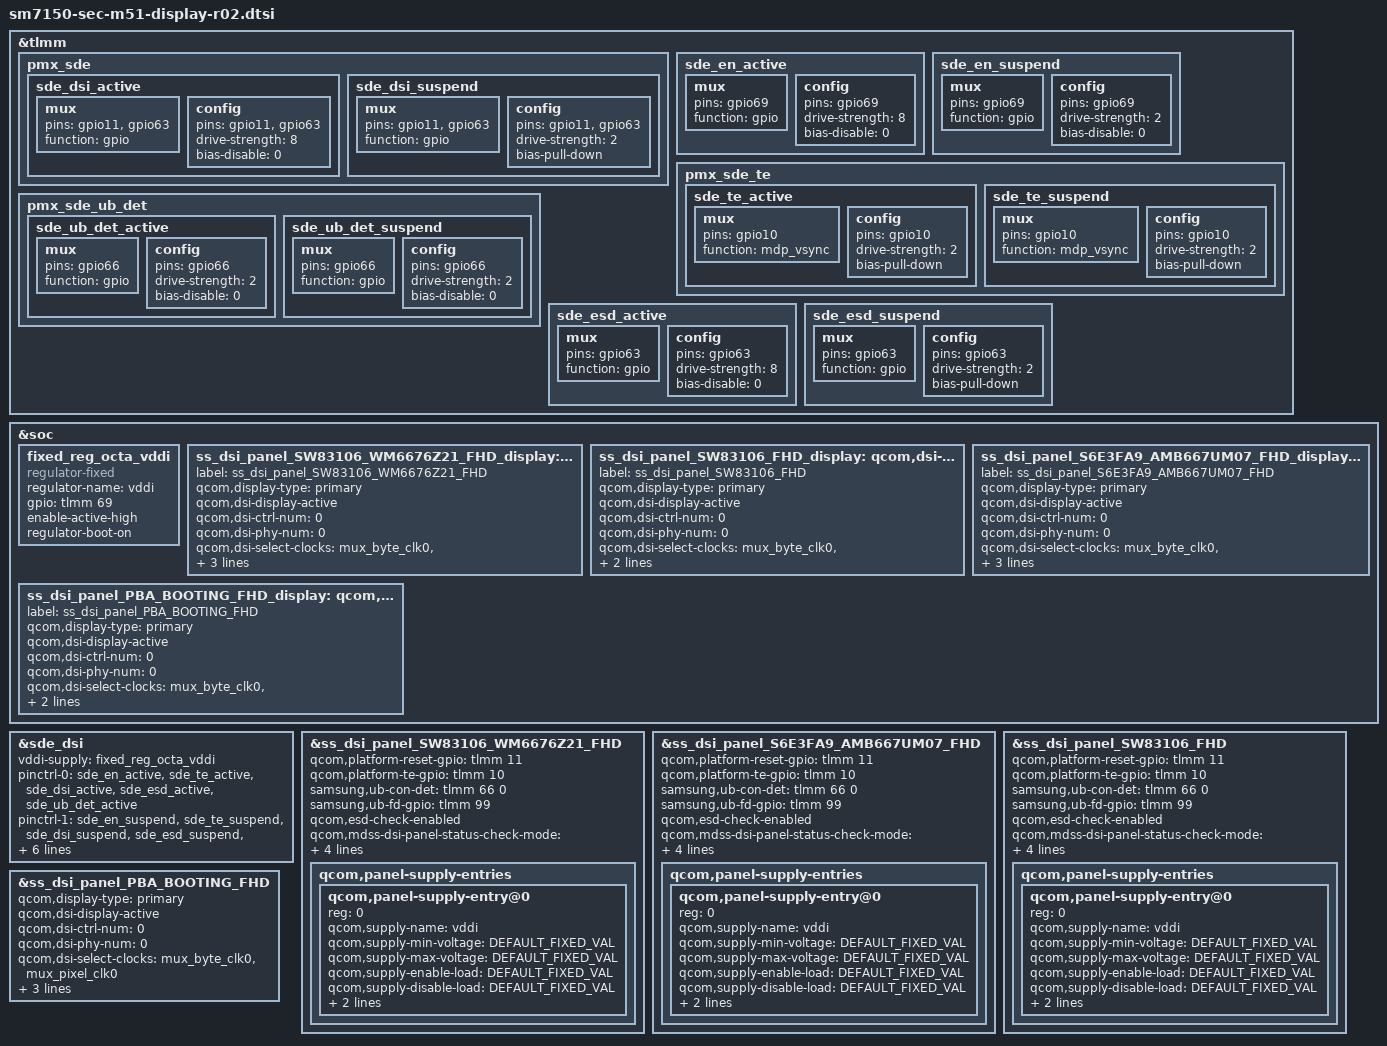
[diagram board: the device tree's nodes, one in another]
/* Copyright (c) 2016-2019, The Linux Foundation. All rights reserved.
 *
 * This program is free software; you can redistribute it and/or modify
 * it under the terms of the GNU General Public License version 2 and
 * only version 2 as published by the Free Software Foundation.
 *
 * This program is distributed in the hope that it will be useful,
 * but WITHOUT ANY WARRANTY; without even the implied warranty of
 * MERCHANTABILITY or FITNESS FOR A PARTICULAR PURPOSE.  See the
 * GNU General Public License for more details.
 */
#include "../../../../../../drivers/gpu/drm/msm/samsung/SW83106/dsi_panel_SW83106_fhd_octa_cmd.dtsi"
#include "../../../../../../drivers/gpu/drm/msm/samsung/SW83106_WM6676Z21/dsi_panel_SW83106_WM6676Z21_fhd_octa_cmd.dtsi"
#include "../../../../../../drivers/gpu/drm/msm/samsung/S6E3FA9_AMB667UM07/dsi_panel_S6E3FA9_AMB667UM07_fhd_octa_cmd.dtsi"
#include "../../../../../../drivers/gpu/drm/msm/samsung/SELF_DISPLAY/self_display_cmd_FA9.dtsi"
#include "../../../../../../drivers/gpu/drm/msm/samsung/PBA_BOOTING/dsi_panel_PBA_BOOTING_fhd_video.dtsi"

#define DEFAULT_FIXED_VAL	0

&tlmm {
	pmx_sde: pmx_sde {
		sde_dsi_active: sde_dsi_active {
			mux {
				pins = "gpio11", "gpio63";
				function = "gpio";
			};

			config {
				pins = "gpio11", "gpio63";
				drive-strength = <8>;   /* 8 mA */
				bias-disable = <0>;   /* no pull */
			};
		};
		sde_dsi_suspend: sde_dsi_suspend {
			mux {
				pins = "gpio11", "gpio63";
				function = "gpio";
			};

			config {
				pins = "gpio11", "gpio63";
				drive-strength = <2>;   /* 2 mA */
				bias-pull-down;         /* PULL DOWN */
			};
		};
	};

		sde_en_active: sde_en_active {
			mux {
				pins = "gpio69";
				function = "gpio";
			};

			config {
				pins = "gpio69";
				drive-strength = <8>;   /* 8 mA */
				bias-disable = <0>;   /* no pull */
			};
		};
		sde_en_suspend: sde_en_suspend {
			mux {
				pins = "gpio69";
				function = "gpio";
			};

			config {
				pins = "gpio69";
				drive-strength = <2>;   /* 2 mA */
				bias-disable = <0>;   /* no pull */
			};
		};

	pmx_sde_te {
		sde_te_active: sde_te_active {
			mux {
				pins = "gpio10";
				function = "mdp_vsync";
			};

			config {
				pins = "gpio10";
				drive-strength = <2>;   /* 2 mA */
				bias-pull-down;         /* PULL DOWN */
			};
		};

		sde_te_suspend: sde_te_suspend {
			mux {
				pins = "gpio10";
				function = "mdp_vsync";
			};

			config {
				pins = "gpio10";
				drive-strength = <2>;   /* 2 mA */
				bias-pull-down;         /* PULL DOWN */
			};
		};
	};

	pmx_sde_ub_det {
		sde_ub_det_active: sde_ub_det_active {	/* UB_CON_DET */
			mux {
				pins = "gpio66";
				function = "gpio";
			};

			config {
				pins = "gpio66";
				drive-strength = <2>;   /* 2 mA */
				bias-disable = <0>;   /* no pull */
			};
		};

		sde_ub_det_suspend: sde_ub_det_suspend {
			mux {
				pins = "gpio66";
				function = "gpio";
			};

			config {
				pins = "gpio66";
				drive-strength = <2>;   /* 2 mA */
				bias-disable = <0>;   /* no pull */
			};
		};
	};

	sde_esd_active: sde_esd_active {  /*EL_ON1_DET gpio*/
		mux {
			pins = "gpio63";
			function = "gpio";
		};

		config {
			pins = "gpio63";
			drive-strength = <8>;   /* 8 mA */
			bias-disable = <0>;   /* no pull */
		};
	};
	sde_esd_suspend: sde_esd_suspend {
		mux {
			pins = "gpio63";
			function = "gpio";
		};

		config {
			pins = "gpio63";
			drive-strength = <2>;   /* 2 mA */
			bias-pull-down;         /* PULL DOWN */
		};
	};
};

&soc {
	fixed_reg_octa_vddi: fixed_reg_octa_vddi {
		compatible = "regulator-fixed";
		status = "okay";
		regulator-name = "vddi";
		gpio = <&tlmm 69 0>; /* LCD_EN : 3.0 & 1.8 V */
		enable-active-high;
		regulator-boot-on;
	};
};

&soc {
	ss_dsi_panel_SW83106_WM6676Z21_FHD_display: qcom,dsi-display@0 {
		label = "ss_dsi_panel_SW83106_WM6676Z21_FHD";
		qcom,display-type = "primary";
		qcom,dsi-display-active;

		qcom,dsi-ctrl-num = <0>;
		qcom,dsi-phy-num = <0>;
		qcom,dsi-select-clocks = "mux_byte_clk0", "mux_pixel_clk0";

		qcom,dsi-panel = <&ss_dsi_panel_SW83106_WM6676Z21_FHD>;
	};

	ss_dsi_panel_SW83106_FHD_display: qcom,dsi-display@1 {
		label = "ss_dsi_panel_SW83106_FHD";
		qcom,display-type = "primary";
		qcom,dsi-display-active;

		qcom,dsi-ctrl-num = <0>;
		qcom,dsi-phy-num = <0>;
		qcom,dsi-select-clocks = "mux_byte_clk0", "mux_pixel_clk0";

		qcom,dsi-panel = <&ss_dsi_panel_SW83106_FHD>;
	};

	ss_dsi_panel_S6E3FA9_AMB667UM07_FHD_display: qcom,dsi-display@2 {
		label = "ss_dsi_panel_S6E3FA9_AMB667UM07_FHD";
		qcom,display-type = "primary";
		qcom,dsi-display-active;

		qcom,dsi-ctrl-num = <0>;
		qcom,dsi-phy-num = <0>;
		qcom,dsi-select-clocks = "mux_byte_clk0", "mux_pixel_clk0";

		qcom,dsi-panel = <&ss_dsi_panel_S6E3FA9_AMB667UM07_FHD>;
	};

	/* PBA */
	ss_dsi_panel_PBA_BOOTING_FHD_display: qcom,dsi-display@3 {
		label = "ss_dsi_panel_PBA_BOOTING_FHD";
		qcom,display-type = "primary";
		qcom,dsi-display-active;

		qcom,dsi-ctrl-num = <0>;
		qcom,dsi-phy-num = <0>;
		qcom,dsi-select-clocks = "mux_byte_clk0", "mux_pixel_clk0";

		qcom,dsi-panel = <&ss_dsi_panel_PBA_BOOTING_FHD>;
	};
};

&sde_dsi {
	vddi-supply = <&fixed_reg_octa_vddi>;

	pinctrl-names = "panel_active", "panel_suspend";
	pinctrl-0 = <&sde_en_active &sde_te_active &sde_dsi_active &sde_esd_active &sde_ub_det_active>;
	pinctrl-1 = <&sde_en_suspend &sde_te_suspend &sde_dsi_suspend &sde_esd_suspend &sde_ub_det_suspend>;

	qcom,dsi-display-list =
		<&ss_dsi_panel_SW83106_WM6676Z21_FHD_display
		&ss_dsi_panel_SW83106_FHD_display
		&ss_dsi_panel_S6E3FA9_AMB667UM07_FHD_display
		&ss_dsi_panel_PBA_BOOTING_FHD_display>;
};

&ss_dsi_panel_SW83106_WM6676Z21_FHD {
	qcom,platform-reset-gpio = <&tlmm 11 0>;    /* UB_RST_N */
	qcom,platform-te-gpio = <&tlmm 10 0>;       /* DISP_TE	  */

	samsung,ub-con-det = <&tlmm 66 0>; // UB_CON_DET
	samsung,ub-fd-gpio = <&tlmm 99 0>; // Fast Discharge

	/* ESD related */
	qcom,esd-check-enabled;
	qcom,mdss-dsi-panel-status-check-mode ="irq_check";
	qcom,mdss-dsi-panel-status-irq-trigger1 = "falling";
	samsung,esd-irq-gpio1 = <&tlmm 63 0>; /* EL_ON1_DET */

	qcom,panel-supply-entries {
		#address-cells = <1>;
		#size-cells = <0>;

		/* use fixed regulator instead of samsung,panel-extra-power-gpio or qcom,platform-enable-gpio. */
		qcom,panel-supply-entry@0 {
			reg = <0>;
			qcom,supply-name = "vddi"; // 3.0V , 1.8V
			qcom,supply-min-voltage = <DEFAULT_FIXED_VAL>;
			qcom,supply-max-voltage = <DEFAULT_FIXED_VAL>;
			qcom,supply-enable-load = <DEFAULT_FIXED_VAL>;
			qcom,supply-disable-load = <DEFAULT_FIXED_VAL>;
			qcom,supply-pre-off-sleep = <0>;
			qcom,supply-post-on-sleep = <0>;
		};
	};
};

&ss_dsi_panel_S6E3FA9_AMB667UM07_FHD {
	qcom,platform-reset-gpio = <&tlmm 11 0>;    /* UB_RST_N */
	qcom,platform-te-gpio = <&tlmm 10 0>;       /* DISP_TE	  */

	samsung,ub-con-det = <&tlmm 66 0>; // UB_CON_DET
	samsung,ub-fd-gpio = <&tlmm 99 0>; // Fast Discharge

	/* ESD related */
	qcom,esd-check-enabled;
	qcom,mdss-dsi-panel-status-check-mode ="irq_check";
	qcom,mdss-dsi-panel-status-irq-trigger1 = "falling";
	samsung,esd-irq-gpio1 = <&tlmm 63 0>; /* EL_ON1_DET */

	qcom,panel-supply-entries {
		#address-cells = <1>;
		#size-cells = <0>;

		/* use fixed regulator instead of samsung,panel-extra-power-gpio or qcom,platform-enable-gpio. */
		qcom,panel-supply-entry@0 {
			reg = <0>;
			qcom,supply-name = "vddi"; // 3.0V , 1.8V
			qcom,supply-min-voltage = <DEFAULT_FIXED_VAL>;
			qcom,supply-max-voltage = <DEFAULT_FIXED_VAL>;
			qcom,supply-enable-load = <DEFAULT_FIXED_VAL>;
			qcom,supply-disable-load = <DEFAULT_FIXED_VAL>;
			qcom,supply-pre-off-sleep = <0>;
			qcom,supply-post-on-sleep = <0>;
		};
	};
};

&ss_dsi_panel_SW83106_FHD {
	qcom,platform-reset-gpio = <&tlmm 11 0>;    /* UB_RST_N */
	qcom,platform-te-gpio = <&tlmm 10 0>;       /* DISP_TE	  */

	samsung,ub-con-det = <&tlmm 66 0>; // UB_CON_DET
	samsung,ub-fd-gpio = <&tlmm 99 0>; // Fast Discharge

	/* ESD related */
	qcom,esd-check-enabled;
	qcom,mdss-dsi-panel-status-check-mode ="irq_check";
	qcom,mdss-dsi-panel-status-irq-trigger1 = "falling";
	samsung,esd-irq-gpio1 = <&tlmm 63 0>; /* EL_ON1_DET */

	qcom,panel-supply-entries {
		#address-cells = <1>;
		#size-cells = <0>;

		/* use fixed regulator instead of samsung,panel-extra-power-gpio or qcom,platform-enable-gpio. */
		qcom,panel-supply-entry@0 {
			reg = <0>;
			qcom,supply-name = "vddi"; // 3.0V , 1.8V
			qcom,supply-min-voltage = <DEFAULT_FIXED_VAL>;
			qcom,supply-max-voltage = <DEFAULT_FIXED_VAL>;
			qcom,supply-enable-load = <DEFAULT_FIXED_VAL>;
			qcom,supply-disable-load = <DEFAULT_FIXED_VAL>;
			qcom,supply-pre-off-sleep = <0>;
			qcom,supply-post-on-sleep = <0>;
		};
	};
};

&ss_dsi_panel_PBA_BOOTING_FHD {
	qcom,display-type = "primary";
	qcom,dsi-display-active;

	qcom,dsi-ctrl-num = <0>;
	qcom,dsi-phy-num = <0>;
	qcom,dsi-select-clocks = "mux_byte_clk0", "mux_pixel_clk0";

	qcom,dsi-panel = <&ss_dsi_panel_PBA_BOOTING_FHD>;

	qcom,platform-reset-gpio = <&tlmm 11 0>;
	qcom,platform-te-gpio = <&tlmm 10 0>;
};

&ss_dsi_panel_S6E3FA9_AMB667UM07_FHD {
	/delete-property/ samsung,fd_on_tx_cmds_revA;
	/delete-property/ samsung,fd_off_tx_cmds_revA;
};
